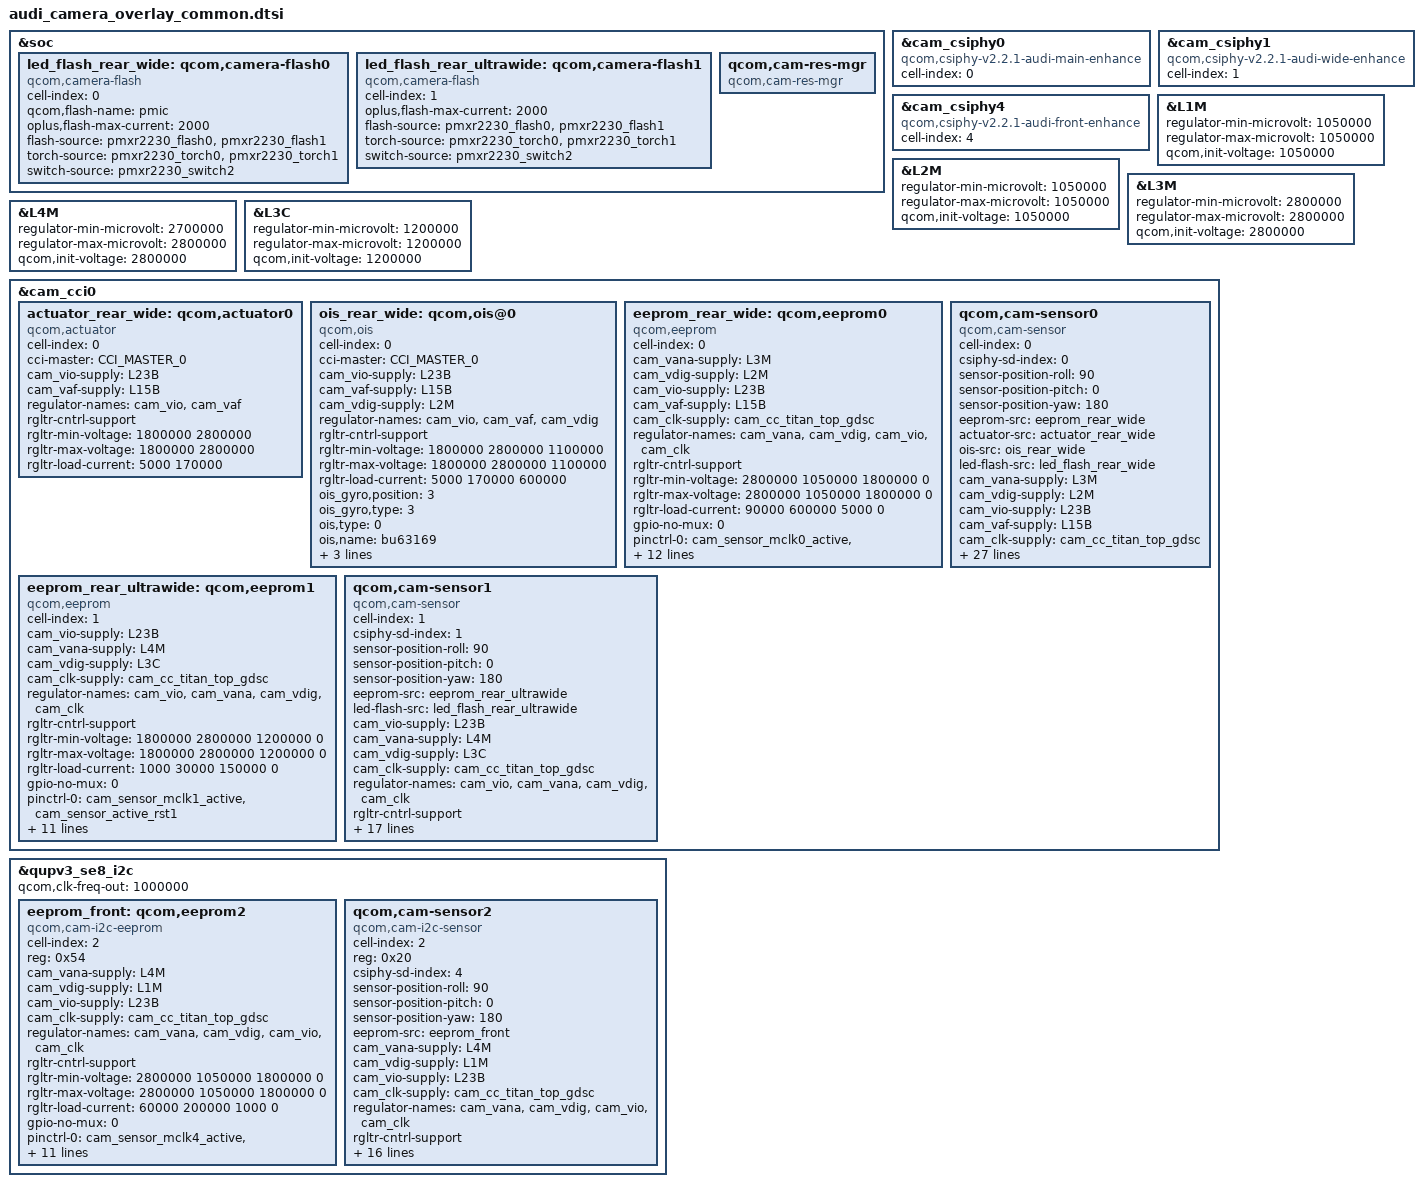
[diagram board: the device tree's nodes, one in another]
#include <dt-bindings/msm-camera.h>

&soc {
	led_flash_rear_wide: qcom,camera-flash0 {
		cell-index = <0>;
		compatible = "qcom,camera-flash";
		qcom,flash-name = "pmic";
		oplus,flash-max-current = <2000>;
		flash-source = <&pmxr2230_flash0 &pmxr2230_flash1>;
		torch-source = <&pmxr2230_torch0 &pmxr2230_torch1>;
		switch-source = <&pmxr2230_switch2>;
		status = "ok";
	};

	led_flash_rear_ultrawide: qcom,camera-flash1 {
		cell-index = <1>;
		compatible = "qcom,camera-flash";
		oplus,flash-max-current = <2000>;
		flash-source = <&pmxr2230_flash0 &pmxr2230_flash1>;
		torch-source = <&pmxr2230_torch0 &pmxr2230_torch1>;
		switch-source = <&pmxr2230_switch2>;
		status = "ok";
	};

	qcom,cam-res-mgr {
		compatible = "qcom,cam-res-mgr";
		status = "ok";
	};
};

&cam_csiphy0{
	cell-index = <0>;
	compatible = "qcom,csiphy-v2.2.1-audi-main-enhance", "qcom,csiphy";
};

&cam_csiphy1{
	cell-index = <1>;
	compatible = "qcom,csiphy-v2.2.1-audi-wide-enhance", "qcom,csiphy";
};

&cam_csiphy4{
	cell-index = <4>;
	compatible = "qcom,csiphy-v2.2.1-audi-front-enhance", "qcom,csiphy";
};

&L1M {
  regulator-min-microvolt = <1050000>;
  regulator-max-microvolt = <1050000>;
  qcom,init-voltage = <1050000>;
};

&L2M {
  regulator-min-microvolt = <1050000>;
  regulator-max-microvolt = <1050000>;
  qcom,init-voltage = <1050000>;
};

&L3M {
  regulator-min-microvolt = <2800000>;
  regulator-max-microvolt = <2800000>;
  qcom,init-voltage = <2800000>;
};

&L4M {
  regulator-min-microvolt = <2700000>;
  regulator-max-microvolt = <2800000>;
  qcom,init-voltage = <2800000>;
};

&L3C {
	regulator-min-microvolt = <1200000>;
	regulator-max-microvolt = <1200000>;
	qcom,init-voltage = <1200000>;
};

&cam_cci0 {
	actuator_rear_wide: qcom,actuator0 {
		cell-index = <0>;
		compatible = "qcom,actuator";
		cci-master = <CCI_MASTER_0>;
		cam_vio-supply = <&L23B>;
		cam_vaf-supply = <&L15B>;
		regulator-names = "cam_vio", "cam_vaf";
		rgltr-cntrl-support;
		rgltr-min-voltage = <1800000 2800000>;
		rgltr-max-voltage = <1800000 2800000>;
		rgltr-load-current = <5000 170000>;
		status = "ok";
	};

	ois_rear_wide: qcom,ois@0{
		cell-index = <0>;
		compatible = "qcom,ois";
		cci-master = <CCI_MASTER_0>;
		cam_vio-supply = <&L23B>;
		cam_vaf-supply = <&L15B>;
		cam_vdig-supply = <&L2M>;
		regulator-names = "cam_vio", "cam_vaf", "cam_vdig";
		rgltr-cntrl-support;
		rgltr-min-voltage = <1800000 2800000 1100000>;
		rgltr-max-voltage = <1800000 2800000 1100000>;
		rgltr-load-current = <5000 170000 600000>;
		ois_gyro,position=<3>;
		ois_gyro,type=<3>;
		ois,type=<0>;
		ois,name="bu63169";
		ois_module,vendor=<1>;
		ois_actuator,vednor=<2>;
		ois,fw=<1>;
		status = "ok";
	};

	eeprom_rear_wide: qcom,eeprom0 {
		cell-index = <0>;
		compatible = "qcom,eeprom";
		cam_vana-supply = <&L3M>;
		cam_vdig-supply = <&L2M>;
		cam_vio-supply = <&L23B>;
		cam_vaf-supply = <&L15B>;
		cam_clk-supply = <&cam_cc_titan_top_gdsc>;
		regulator-names = "cam_vana", "cam_vdig", "cam_vio",
		                  "cam_clk";
		rgltr-cntrl-support;
		rgltr-min-voltage = <2800000 1050000 1800000  0>;
		rgltr-max-voltage = <2800000 1050000 1800000  0>;
		rgltr-load-current = <90000 600000 5000 0>;
		gpio-no-mux = <0>;
		pinctrl-names = "cam_default", "cam_suspend";
		pinctrl-0 = <&cam_sensor_mclk0_active
			&cam_sensor_active_rst0>;
		pinctrl-1 = <&cam_sensor_mclk0_suspend
			&cam_sensor_suspend_rst0>;
		gpios = <&tlmm 64 0>,
			<&tlmm 15 0>;
		gpio-reset = <1>;
		gpio-req-tbl-num = <0 1>;
		gpio-req-tbl-flags = <1 0>;
		gpio-req-tbl-label = "CAMIF_MCLK0",
					"CAM_RESET0";
		cci-master = <CCI_MASTER_0>;
		clocks = <&camcc CAM_CC_MCLK0_CLK>;
		clock-names = "cam_clk";
		clock-cntl-level = "nominal";
		clock-rates = <24000000>;
		status = "ok";
	};

	qcom,cam-sensor0 {
		cell-index = <0>;
		compatible = "qcom,cam-sensor";
		csiphy-sd-index = <0>;
		sensor-position-roll = <90>;
		sensor-position-pitch = <0>;
		sensor-position-yaw = <180>;
		eeprom-src = <&eeprom_rear_wide>;
		actuator-src = <&actuator_rear_wide>;
		ois-src = <&ois_rear_wide>;
		led-flash-src = <&led_flash_rear_wide>;
		cam_vana-supply = <&L3M>;
		cam_vdig-supply = <&L2M>;
		cam_vio-supply = <&L23B>;
		cam_vaf-supply = <&L15B>;
		cam_clk-supply = <&cam_cc_titan_top_gdsc>;
		regulator-names = "cam_vana", "cam_vdig", "cam_vio","cam_vaf",
		                  "cam_clk";
		rgltr-cntrl-support;
		rgltr-min-voltage = <2800000 1050000 1800000  2700000 0>;
		rgltr-max-voltage = <2800000 1050000 1800000  2800000 0>;
		rgltr-load-current = <90000 600000 5000 170000 0>;
		gpio-no-mux = <0>;
		pinctrl-names = "cam_default", "cam_suspend";
		pinctrl-0 = <&cam_sensor_mclk0_active
			&cam_sensor_active_rst0>;
		pinctrl-1 = <&cam_sensor_mclk0_suspend
			&cam_sensor_suspend_rst0>;
		gpios = <&tlmm 64 0>,
			<&tlmm 15 0>;
		gpio-reset = <1>;
		gpio-req-tbl-num = <0 1>;
		gpio-req-tbl-flags = <1 0>;
		gpio-req-tbl-label = "CAMIF_MCLK0",
					"CAM_RESET0";
		cci-master = <CCI_MASTER_0>;
		clocks = <&camcc CAM_CC_MCLK0_CLK>;
		clock-names = "cam_clk";
		clock-cntl-level = "nominal";
		clock-rates = <24000000>;
		enable_qsc_write_in_advance = <1>;
		qsc_reg_addr = <0x2210>;
		eeprom_slave_addr = <0xA0>;
		qsc_data_size = <3072>;
		write_qsc_addr = <0xC000>;
		status = "ok";
	};

	eeprom_rear_ultrawide: qcom,eeprom1 {
		cell-index = <1>;
		compatible = "qcom,eeprom";
		cam_vio-supply = <&L23B>;
		cam_vana-supply = <&L4M>;
		cam_vdig-supply = <&L3C>;
		cam_clk-supply = <&cam_cc_titan_top_gdsc>;
		regulator-names = "cam_vio", "cam_vana", "cam_vdig", "cam_clk";
		rgltr-cntrl-support;
		rgltr-min-voltage = <1800000 2800000 1200000 0>;
		rgltr-max-voltage = <1800000 2800000 1200000 0>;
		rgltr-load-current = <1000 30000 150000 0>;
		gpio-no-mux = <0>;
		pinctrl-names = "cam_default", "cam_suspend";
		pinctrl-0 = <&cam_sensor_mclk1_active
				 &cam_sensor_active_rst1>;
		pinctrl-1 = <&cam_sensor_mclk1_suspend
				 &cam_sensor_suspend_rst1>;
		gpios = <&tlmm 65 0>,
			<&tlmm 14 0>;
		gpio-reset = <1>;
		gpio-req-tbl-num = <0 1>;
		gpio-req-tbl-flags = <1 0>;
		gpio-req-tbl-label = "CAMIF_MCLK1",
					"CAM_RESET1";
		cci-master = <CCI_MASTER_1>;
		clocks = <&camcc CAM_CC_MCLK1_CLK>;
		clock-names = "cam_clk";
		clock-cntl-level = "nominal";
		clock-rates = <19200000>;
		status = "ok";
	};

	qcom,cam-sensor1 {
		cell-index = <1>;
		compatible = "qcom,cam-sensor";
		csiphy-sd-index = <1>;
		sensor-position-roll = <90>;
		sensor-position-pitch = <0>;
		sensor-position-yaw = <180>;
		eeprom-src = <&eeprom_rear_ultrawide>;
		led-flash-src = <&led_flash_rear_ultrawide>;
		cam_vio-supply = <&L23B>;
		cam_vana-supply = <&L4M>;
		cam_vdig-supply = <&L3C>;
		cam_clk-supply = <&cam_cc_titan_top_gdsc>;
		regulator-names = "cam_vio", "cam_vana", "cam_vdig", "cam_clk";
		rgltr-cntrl-support;
		rgltr-min-voltage = <1800000 2800000 1200000 0>;
		rgltr-max-voltage = <1800000 2800000 1200000 0>;
		rgltr-load-current = <1000 30000 148000 0>;
		gpio-no-mux = <0>;
		pinctrl-names = "cam_default", "cam_suspend";
		pinctrl-0 = <&cam_sensor_mclk1_active
				 &cam_sensor_active_rst1>;
		pinctrl-1 = <&cam_sensor_mclk1_suspend
				 &cam_sensor_suspend_rst1>;
		gpios = <&tlmm 65 0>,
			<&tlmm 14 0>;
		gpio-reset = <1>;
		gpio-req-tbl-num = <0 1>;
		gpio-req-tbl-flags = <1 0>;
		gpio-req-tbl-label = "CAMIF_MCLK1",
					"CAM_RESET1";
		cci-master = <CCI_MASTER_1>;
		clocks = <&camcc CAM_CC_MCLK1_CLK>;
		clock-names = "cam_clk";
		clock-cntl-level = "nominal";
		clock-rates = <19200000>;
		status = "ok";
	};

};

&qupv3_se8_i2c {

    status = "ok";
	qcom,clk-freq-out = <1000000>;

	eeprom_front: qcom,eeprom2 {
		cell-index = <2>;
		reg = <0x54>;
		compatible = "qcom,cam-i2c-eeprom";
		cam_vana-supply = <&L4M>;
		cam_vdig-supply = <&L1M>;
		cam_vio-supply = <&L23B>;
		cam_clk-supply = <&cam_cc_titan_top_gdsc>;
		regulator-names = "cam_vana", "cam_vdig", "cam_vio", "cam_clk";
		rgltr-cntrl-support;
		// aon-user;
		rgltr-min-voltage = <2800000 1050000 1800000 0>;
		rgltr-max-voltage = <2800000 1050000 1800000 0>;
		rgltr-load-current = <60000 200000 1000 0>;
		gpio-no-mux = <0>;
		pinctrl-names = "cam_default", "cam_suspend";
		pinctrl-0 = <&cam_sensor_mclk4_active
					 &cam_sensor_active_rst4>;
		pinctrl-1 = <&cam_sensor_mclk4_suspend
				 &cam_sensor_suspend_rst4>;
		gpios = <&tlmm 68 0>,
			<&tlmm 3 0>;
		gpio-reset = <1>;
		gpio-req-tbl-num = <0 1>;
		gpio-req-tbl-flags = <1 0>;
		gpio-req-tbl-label = "CAMIF_MCLK4",
					"CAM_RESET3";
		clocks = <&camcc CAM_CC_MCLK4_CLK>;
		clock-names = "cam_clk";
		clock-cntl-level = "nominal";
		clock-rates = <19200000>;
		status = "ok";
	};

	qcom,cam-sensor2 {
			cell-index = <2>;
			compatible = "qcom,cam-i2c-sensor";
			reg = <0x20>;
			csiphy-sd-index = <4>;
			sensor-position-roll = <90>;
			sensor-position-pitch = <0>;
			sensor-position-yaw = <180>;
			eeprom-src = <&eeprom_front>;
			cam_vana-supply = <&L4M>;
			cam_vdig-supply = <&L1M>;
			cam_vio-supply = <&L23B>;
			cam_clk-supply = <&cam_cc_titan_top_gdsc>;
			regulator-names = "cam_vana", "cam_vdig", "cam_vio", "cam_clk";
			rgltr-cntrl-support;
			rgltr-min-voltage = <2800000 1050000 1800000 0>;
			rgltr-max-voltage = <2800000 1050000 1800000 0>;
			rgltr-load-current = <60000 200000 1000 0>;
			gpio-no-mux = <0>;
			pinctrl-names = "cam_default", "cam_suspend";
			pinctrl-0 = <&cam_sensor_mclk4_active
					 &cam_sensor_active_rst4>;
			pinctrl-1 = <&cam_sensor_mclk4_suspend
					 &cam_sensor_suspend_rst4>;
			gpios = <&tlmm 68 0>,
				<&tlmm 3 0>;
			gpio-reset = <1>;
			gpio-req-tbl-num = <0 1>;
			gpio-req-tbl-flags = <1 0>;
			gpio-req-tbl-label = "CAMIF_MCLK4",
						"CAM_RESET3";
			clocks = <&camcc CAM_CC_MCLK4_CLK>;
			clock-names = "cam_clk";
			clock-cntl-level = "nominal";
			clock-rates = <19200000>;
			status = "ok";
		};

};

